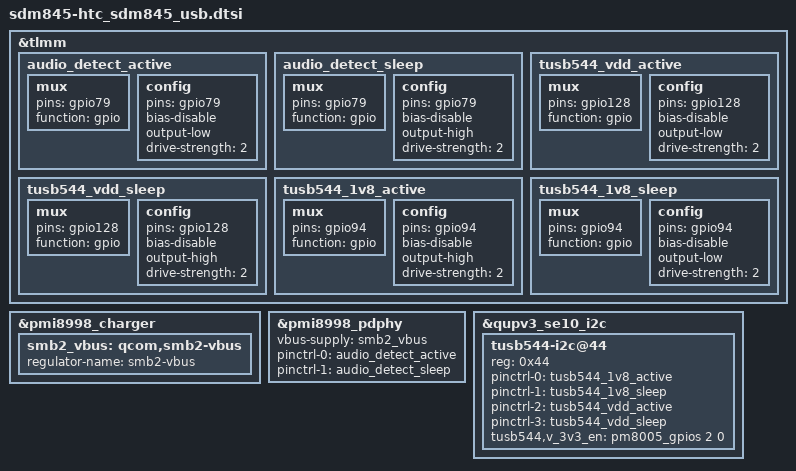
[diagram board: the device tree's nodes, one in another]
/* Copyright (c) 2017, The Linux Foundation. All rights reserved.
 *
 * This program is free software; you can redistribute it and/or modify
 * it under the terms of the GNU General Public License version 2 and
 * only version 2 as published by the Free Software Foundation.
 *
 * This program is distributed in the hope that it will be useful,
 * but WITHOUT ANY WARRANTY; without even the implied warranty of
 * MERCHANTABILITY or FITNESS FOR A PARTICULAR PURPOSE.  See the
 * GNU General Public License for more details.
 */

/*
 * sdm845-htc_sdm845-usb: usb related config
 */

&tlmm {
	audio_detect_active: audio_detect_active {
		mux {
			pins = "gpio79";
			function = "gpio";
		};

		config {
			pins = "gpio79";
			bias-disable;
			output-low;
			drive-strength = <2>;
		};
	};

	audio_detect_sleep: audio_detect_sleep {
		mux {
			pins = "gpio79";
			function = "gpio";
		};

		config {
			pins = "gpio79";
			bias-disable;
			output-high;
			drive-strength = <2>;
		};
	};

	tusb544_vdd_active: tusb544_vdd_active {
			mux {
				pins = "gpio128";
				function = "gpio";
			};

			config {
				pins = "gpio128";
				bias-disable;
				output-low;
				drive-strength = <2>;
			};
	};

	tusb544_vdd_sleep: tusb544_vdd_sleep {
			mux {
				pins = "gpio128";
				function = "gpio";
			};

			config {
				pins = "gpio128";
				bias-disable;
				output-high;
				drive-strength = <2>;
			};
	};

	tusb544_1v8_active: tusb544_1v8_active {
			mux {
				pins = "gpio94";
				function = "gpio";
			};

			config {
				pins = "gpio94";
				bias-disable;
				output-high;
				drive-strength = <2>;
			};
	};

	tusb544_1v8_sleep: tusb544_1v8_sleep {
			mux {
				pins = "gpio94";
				function = "gpio";
			};

			config {
				pins = "gpio94";
				bias-disable;
				output-low;
				drive-strength = <2>;
			};
	};
};

&pmi8998_charger {
	smb2_vbus: qcom,smb2-vbus {
		regulator-name = "smb2-vbus";
	};
};

&pmi8998_pdphy {
	vbus-supply = <&smb2_vbus>;/*override pmi8998.dtsi in evm stage*/
	pinctrl-names = "pin_active" , "pin_sleep";
	pinctrl-0 = <&audio_detect_active>;
	pinctrl-1 = <&audio_detect_sleep>;
};

&qupv3_se10_i2c {
	status = "ok";
	tusb544-i2c@44 {
		/*compatible = "ti,tusb544-i2c";*/
		reg = <0x44>;
		pinctrl-names = "tusb544_pin_active", "tusb544_pin_sleep", "tusb544_vdd_active", "tusb544_vdd_sleep";
		pinctrl-0 = <&tusb544_1v8_active>;
		pinctrl-1 = <&tusb544_1v8_sleep>;
		pinctrl-2 = <&tusb544_vdd_active>;
		pinctrl-3 = <&tusb544_vdd_sleep>;

		tusb544,v_3v3_en = <&pm8005_gpios 2 0>;
	};
};
